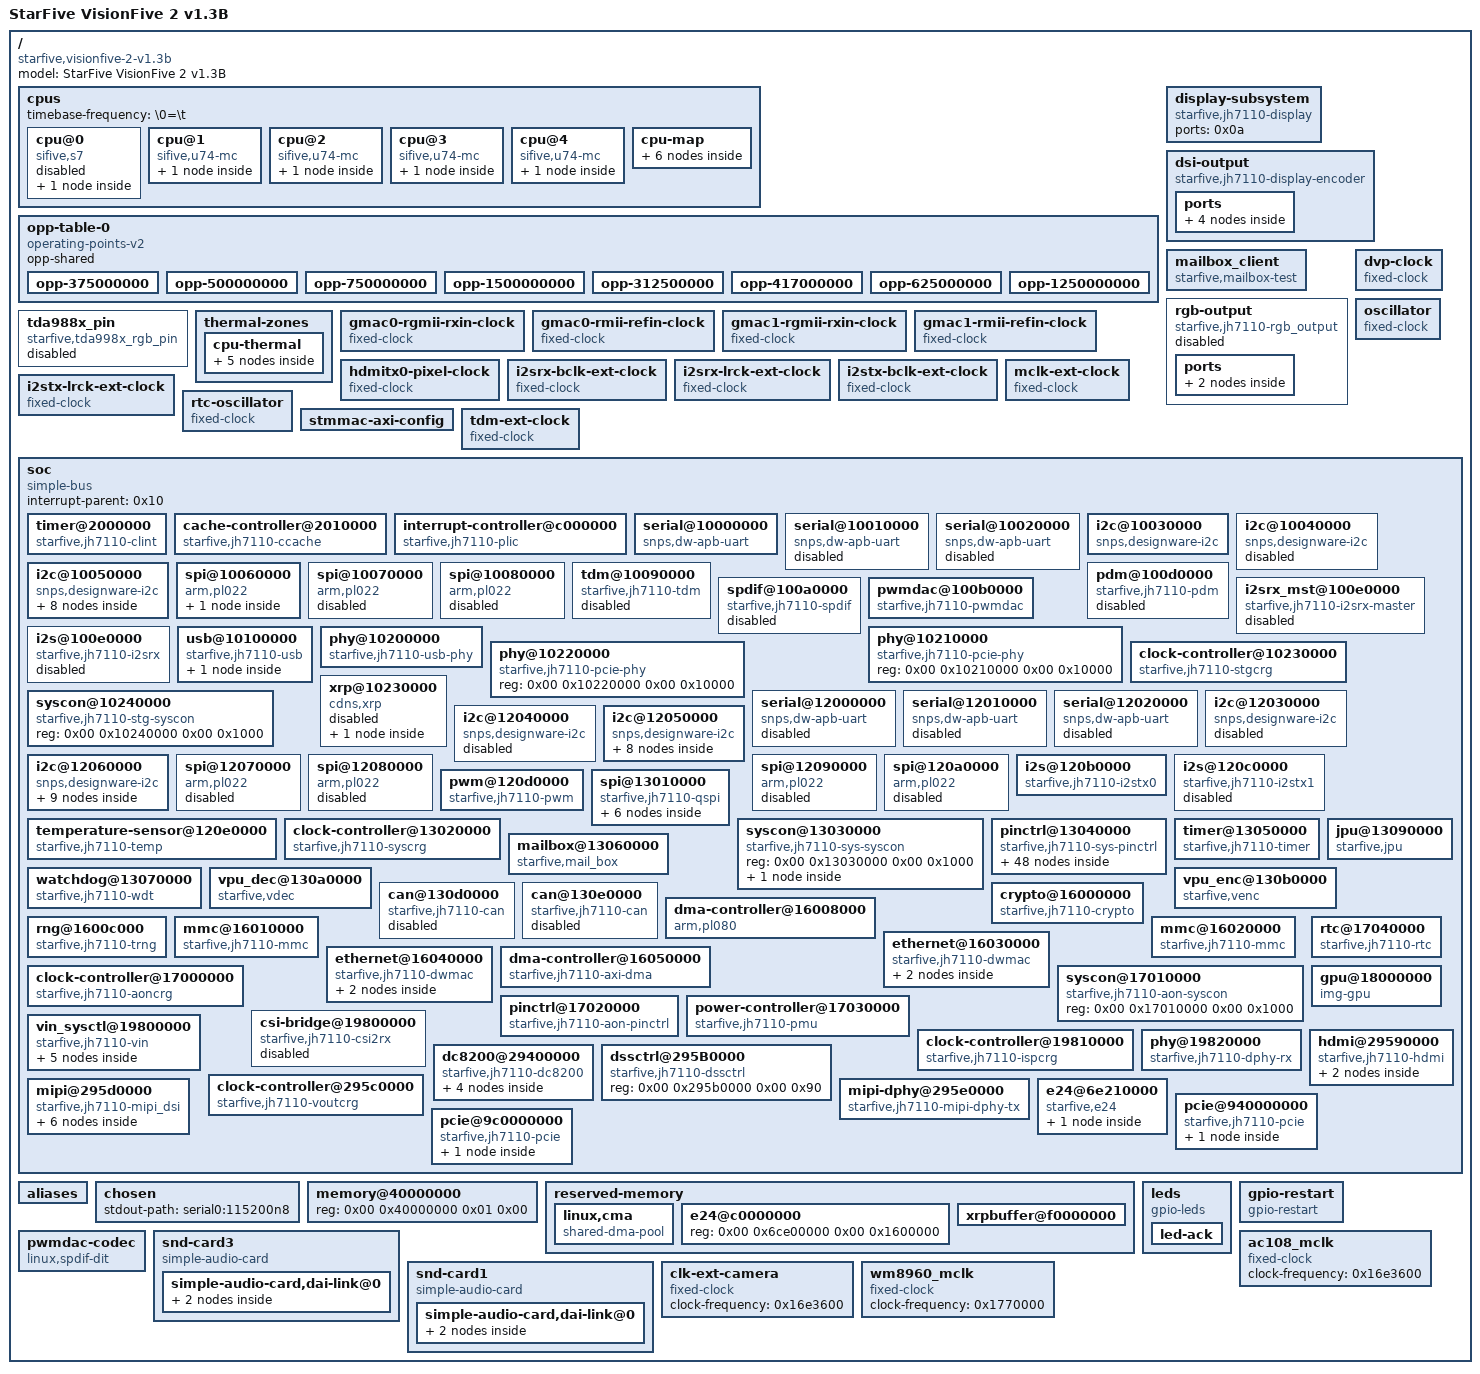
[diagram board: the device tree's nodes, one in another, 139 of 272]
/dts-v1/;

/ {
	compatible = "starfive,visionfive-2-v1.3b\0starfive,jh7110";
	#address-cells = <0x02>;
	#size-cells = <0x02>;
	model = "StarFive VisionFive 2 v1.3B";

	cpus {
		#address-cells = <0x01>;
		#size-cells = <0x00>;
		timebase-frequency = "\0=\t";

		cpu@0 {
			compatible = "sifive,s7\0riscv";
			reg = <0x00>;
			device_type = "cpu";
			i-cache-block-size = <0x40>;
			i-cache-sets = <0x40>;
			i-cache-size = <0x4000>;
			next-level-cache = <0x01>;
			riscv,isa = "rv64imac_zba_zbb";
			status = "disabled";
			phandle = <0x05>;

			interrupt-controller {
				compatible = "riscv,cpu-intc";
				interrupt-controller;
				#interrupt-cells = <0x01>;
				phandle = <0x11>;
			};
		};

		cpu@1 {
			compatible = "sifive,u74-mc\0riscv";
			reg = <0x01>;
			d-cache-block-size = <0x40>;
			d-cache-sets = <0x40>;
			d-cache-size = <0x8000>;
			d-tlb-sets = <0x01>;
			d-tlb-size = <0x28>;
			device_type = "cpu";
			i-cache-block-size = <0x40>;
			i-cache-sets = <0x40>;
			i-cache-size = <0x8000>;
			i-tlb-sets = <0x01>;
			i-tlb-size = <0x28>;
			mmu-type = "riscv,sv39";
			next-level-cache = <0x01>;
			riscv,isa = "rv64imafdc_zba_zbb";
			tlb-split;
			operating-points-v2 = <0x02>;
			clocks = <0x03 0x01>;
			clock-names = "cpu";
			#cooling-cells = <0x02>;
			cpu-supply = <0x04>;
			phandle = <0x06>;

			interrupt-controller {
				compatible = "riscv,cpu-intc";
				interrupt-controller;
				#interrupt-cells = <0x01>;
				phandle = <0x12>;
			};
		};

		cpu@2 {
			compatible = "sifive,u74-mc\0riscv";
			reg = <0x02>;
			d-cache-block-size = <0x40>;
			d-cache-sets = <0x40>;
			d-cache-size = <0x8000>;
			d-tlb-sets = <0x01>;
			d-tlb-size = <0x28>;
			device_type = "cpu";
			i-cache-block-size = <0x40>;
			i-cache-sets = <0x40>;
			i-cache-size = <0x8000>;
			i-tlb-sets = <0x01>;
			i-tlb-size = <0x28>;
			mmu-type = "riscv,sv39";
			next-level-cache = <0x01>;
			riscv,isa = "rv64imafdc_zba_zbb";
			tlb-split;
			operating-points-v2 = <0x02>;
			clocks = <0x03 0x01>;
			clock-names = "cpu";
			#cooling-cells = <0x02>;
			cpu-supply = <0x04>;
			phandle = <0x07>;

			interrupt-controller {
				compatible = "riscv,cpu-intc";
				interrupt-controller;
				#interrupt-cells = <0x01>;
				phandle = <0x13>;
			};
		};

		cpu@3 {
			compatible = "sifive,u74-mc\0riscv";
			reg = <0x03>;
			d-cache-block-size = <0x40>;
			d-cache-sets = <0x40>;
			d-cache-size = <0x8000>;
			d-tlb-sets = <0x01>;
			d-tlb-size = <0x28>;
			device_type = "cpu";
			i-cache-block-size = <0x40>;
			i-cache-sets = <0x40>;
			i-cache-size = <0x8000>;
			i-tlb-sets = <0x01>;
			i-tlb-size = <0x28>;
			mmu-type = "riscv,sv39";
			next-level-cache = <0x01>;
			riscv,isa = "rv64imafdc_zba_zbb";
			tlb-split;
			operating-points-v2 = <0x02>;
			clocks = <0x03 0x01>;
			clock-names = "cpu";
			#cooling-cells = <0x02>;
			cpu-supply = <0x04>;
			phandle = <0x08>;

			interrupt-controller {
				compatible = "riscv,cpu-intc";
				interrupt-controller;
				#interrupt-cells = <0x01>;
				phandle = <0x14>;
			};
		};

		cpu@4 {
			compatible = "sifive,u74-mc\0riscv";
			reg = <0x04>;
			d-cache-block-size = <0x40>;
			d-cache-sets = <0x40>;
			d-cache-size = <0x8000>;
			d-tlb-sets = <0x01>;
			d-tlb-size = <0x28>;
			device_type = "cpu";
			i-cache-block-size = <0x40>;
			i-cache-sets = <0x40>;
			i-cache-size = <0x8000>;
			i-tlb-sets = <0x01>;
			i-tlb-size = <0x28>;
			mmu-type = "riscv,sv39";
			next-level-cache = <0x01>;
			riscv,isa = "rv64imafdc_zba_zbb";
			tlb-split;
			operating-points-v2 = <0x02>;
			clocks = <0x03 0x01>;
			clock-names = "cpu";
			#cooling-cells = <0x02>;
			cpu-supply = <0x04>;
			phandle = <0x09>;

			interrupt-controller {
				compatible = "riscv,cpu-intc";
				interrupt-controller;
				#interrupt-cells = <0x01>;
				phandle = <0x15>;
			};
		};

		cpu-map {

			cluster0 {

				core0 {
					cpu = <0x05>;
				};

				core1 {
					cpu = <0x06>;
				};

				core2 {
					cpu = <0x07>;
				};

				core3 {
					cpu = <0x08>;
				};

				core4 {
					cpu = <0x09>;
				};
			};
		};
	};

	opp-table-0 {
		compatible = "operating-points-v2";
		opp-shared;
		phandle = <0x02>;

		opp-375000000 {
			opp-hz = <0x00 0x165a0bc0>;
			opp-microvolt = <0xdbba0>;
		};

		opp-500000000 {
			opp-hz = <0x00 0x1dcd6500>;
			opp-microvolt = <0xdbba0>;
		};

		opp-750000000 {
			opp-hz = <0x00 0x2cb41780>;
			opp-microvolt = <0xdbba0>;
			opp-suspend;
		};

		opp-1500000000 {
			opp-hz = <0x00 0x59682f00>;
			opp-microvolt = <0xfde80>;
		};

		opp-312500000 {
			opp-hz = <0x00 0x12a05f20>;
			opp-microvolt = <0xdbba0>;
		};

		opp-417000000 {
			opp-hz = <0x00 0x18daea40>;
			opp-microvolt = <0xdbba0>;
		};

		opp-625000000 {
			opp-hz = <0x00 0x2540be40>;
			opp-microvolt = <0xdbba0>;
			opp-suspend;
		};

		opp-1250000000 {
			opp-hz = <0x00 0x4a817c80>;
			opp-microvolt = <0xf4240>;
		};
	};

	display-subsystem {
		compatible = "starfive,jh7110-display\0verisilicon,display-subsystem";
		status = "okay";
		ports = <0x0a>;
		phandle = <0x69>;
	};

	dsi-output {
		compatible = "starfive,jh7110-display-encoder\0verisilicon,dsi-encoder";
		status = "okay";
		phandle = <0x6a>;

		ports {
			#address-cells = <0x01>;
			#size-cells = <0x00>;

			port@0 {
				reg = <0x00>;

				endpoint {
					remote-endpoint = <0x0b>;
					phandle = <0x52>;
				};
			};

			port@1 {
				reg = <0x01>;

				endpoint {
					remote-endpoint = <0x0c>;
					phandle = <0x5a>;
				};
			};
		};
	};

	mailbox_client {
		compatible = "starfive,mailbox-test";
		mbox-names = "rx\0tx";
		mboxes = <0x0d 0x00 0x01 0x0d 0x01 0x00>;
		status = "okay";
		phandle = <0x6b>;
	};

	rgb-output {
		compatible = "starfive,jh7110-rgb_output\0verisilicon,rgb-encoder";
		status = "disabled";
		phandle = <0x6c>;

		ports {
			#address-cells = <0x01>;
			#size-cells = <0x00>;

			port@0 {
				#address-cells = <0x01>;
				#size-cells = <0x00>;
				reg = <0x00>;

				endpoint@0 {
					reg = <0x00>;
					remote-endpoint = <0x0a>;
					phandle = <0x50>;
				};
			};
		};
	};

	tda988x_pin {
		compatible = "starfive,tda998x_rgb_pin";
		status = "disabled";
		phandle = <0x6d>;
	};

	thermal-zones {

		cpu-thermal {
			polling-delay-passive = <0xfa>;
			polling-delay = <0x3a98>;
			thermal-sensors = <0x0e>;

			cooling-maps {

				map0 {
					trip = <0x0f>;
					cooling-device = <0x06 0xffffffff 0xffffffff 0x07 0xffffffff 0xffffffff 0x08 0xffffffff 0xffffffff 0x09 0xffffffff 0xffffffff>;
				};
			};

			trips {

				cpu_alert0 {
					temperature = <0x14c08>;
					hysteresis = <0x7d0>;
					type = "passive";
					phandle = <0x0f>;
				};

				cpu_crit {
					temperature = <0x186a0>;
					hysteresis = <0x7d0>;
					type = "critical";
				};
			};
		};
	};

	dvp-clock {
		compatible = "fixed-clock";
		clock-output-names = "dvp_clk";
		#clock-cells = <0x00>;
		clock-frequency = <0x46cf710>;
		phandle = <0x4c>;
	};

	gmac0-rgmii-rxin-clock {
		compatible = "fixed-clock";
		clock-output-names = "gmac0_rgmii_rxin";
		#clock-cells = <0x00>;
		clock-frequency = <0x7735940>;
		phandle = <0x44>;
	};

	gmac0-rmii-refin-clock {
		compatible = "fixed-clock";
		clock-output-names = "gmac0_rmii_refin";
		#clock-cells = <0x00>;
		clock-frequency = <0x2faf080>;
		phandle = <0x43>;
	};

	gmac1-rgmii-rxin-clock {
		compatible = "fixed-clock";
		clock-output-names = "gmac1_rgmii_rxin";
		#clock-cells = <0x00>;
		clock-frequency = <0x7735940>;
		phandle = <0x36>;
	};

	gmac1-rmii-refin-clock {
		compatible = "fixed-clock";
		clock-output-names = "gmac1_rmii_refin";
		#clock-cells = <0x00>;
		clock-frequency = <0x2faf080>;
		phandle = <0x35>;
	};

	hdmitx0-pixel-clock {
		compatible = "fixed-clock";
		clock-output-names = "hdmitx0_pixelclk";
		#clock-cells = <0x00>;
		clock-frequency = <0x11b3dc40>;
		phandle = <0x4f>;
	};

	i2srx-bclk-ext-clock {
		compatible = "fixed-clock";
		clock-output-names = "i2srx_bclk_ext";
		#clock-cells = <0x00>;
		clock-frequency = <0xbb8000>;
		phandle = <0x23>;
	};

	i2srx-lrck-ext-clock {
		compatible = "fixed-clock";
		clock-output-names = "i2srx_lrck_ext";
		#clock-cells = <0x00>;
		clock-frequency = <0x2ee00>;
		phandle = <0x24>;
	};

	i2stx-bclk-ext-clock {
		compatible = "fixed-clock";
		clock-output-names = "i2stx_bclk_ext";
		#clock-cells = <0x00>;
		clock-frequency = <0xbb8000>;
		phandle = <0x31>;
	};

	i2stx-lrck-ext-clock {
		compatible = "fixed-clock";
		clock-output-names = "i2stx_lrck_ext";
		#clock-cells = <0x00>;
		clock-frequency = <0x2ee00>;
		phandle = <0x32>;
	};

	mclk-ext-clock {
		compatible = "fixed-clock";
		clock-output-names = "mclk_ext";
		#clock-cells = <0x00>;
		clock-frequency = <0xbb8000>;
		phandle = <0x20>;
	};

	oscillator {
		compatible = "fixed-clock";
		clock-output-names = "osc";
		#clock-cells = <0x00>;
		clock-frequency = <0x16e3600>;
		phandle = <0x29>;
	};

	rtc-oscillator {
		compatible = "fixed-clock";
		clock-output-names = "rtc_osc";
		#clock-cells = <0x00>;
		clock-frequency = <0x8000>;
		phandle = <0x45>;
	};

	stmmac-axi-config {
		snps,lpi_en;
		snps,wr_osr_lmt = <0x0f>;
		snps,rd_osr_lmt = <0x0f>;
		snps,blen = <0x100 0x80 0x40 0x20 0x00 0x00 0x00>;
		phandle = <0x3f>;
	};

	tdm-ext-clock {
		compatible = "fixed-clock";
		clock-output-names = "tdm_ext";
		#clock-cells = <0x00>;
		clock-frequency = <0x2ee0000>;
		phandle = <0x1d>;
	};

	soc {
		compatible = "simple-bus";
		interrupt-parent = <0x10>;
		#address-cells = <0x02>;
		#size-cells = <0x02>;
		ranges;

		timer@2000000 {
			compatible = "starfive,jh7110-clint\0sifive,clint0";
			reg = <0x00 0x2000000 0x00 0x10000>;
			interrupts-extended = <0x11 0x03 0x11 0x07 0x12 0x03 0x12 0x07 0x13 0x03 0x13 0x07 0x14 0x03 0x14 0x07 0x15 0x03 0x15 0x07>;
			phandle = <0x6e>;
		};

		cache-controller@2010000 {
			compatible = "starfive,jh7110-ccache\0sifive,ccache0\0cache";
			reg = <0x00 0x2010000 0x00 0x4000 0x00 0x8000000 0x00 0x2000000 0x00 0xa000000 0x00 0x2000000>;
			interrupts = <0x01 0x03 0x04 0x02>;
			cache-block-size = <0x40>;
			cache-level = <0x02>;
			cache-sets = <0x800>;
			cache-size = <0x200000>;
			cache-unified;
			phandle = <0x01>;
		};

		interrupt-controller@c000000 {
			compatible = "starfive,jh7110-plic\0sifive,plic-1.0.0";
			reg = <0x00 0xc000000 0x00 0x4000000>;
			interrupts-extended = <0x11 0x0b 0x12 0x0b 0x12 0x09 0x13 0x0b 0x13 0x09 0x14 0x0b 0x14 0x09 0x15 0x0b 0x15 0x09>;
			interrupt-controller;
			#interrupt-cells = <0x01>;
			#address-cells = <0x00>;
			riscv,ndev = <0x88>;
			phandle = <0x10>;
		};

		serial@10000000 {
			compatible = "snps,dw-apb-uart";
			reg = <0x00 0x10000000 0x00 0x10000>;
			clocks = <0x03 0x92 0x03 0x91>;
			clock-names = "baudclk\0apb_pclk";
			resets = <0x03 0x53 0x03 0x54>;
			interrupts = <0x20>;
			reg-io-width = <0x04>;
			reg-shift = <0x02>;
			status = "okay";
			pinctrl-names = "default";
			pinctrl-0 = <0x16>;
			phandle = <0x6f>;
		};

		serial@10010000 {
			compatible = "snps,dw-apb-uart";
			reg = <0x00 0x10010000 0x00 0x10000>;
			clocks = <0x03 0x94 0x03 0x93>;
			clock-names = "baudclk\0apb_pclk";
			resets = <0x03 0x55 0x03 0x56>;
			interrupts = <0x21>;
			reg-io-width = <0x04>;
			reg-shift = <0x02>;
			status = "disabled";
			phandle = <0x70>;
		};

		serial@10020000 {
			compatible = "snps,dw-apb-uart";
			reg = <0x00 0x10020000 0x00 0x10000>;
			clocks = <0x03 0x96 0x03 0x95>;
			clock-names = "baudclk\0apb_pclk";
			resets = <0x03 0x57 0x03 0x58>;
			interrupts = <0x22>;
			reg-io-width = <0x04>;
			reg-shift = <0x02>;
			status = "disabled";
			phandle = <0x71>;
		};

		i2c@10030000 {
			compatible = "snps,designware-i2c";
			reg = <0x00 0x10030000 0x00 0x10000>;
			clocks = <0x03 0x8a>;
			clock-names = "ref";
			resets = <0x03 0x4c>;
			interrupts = <0x23>;
			#address-cells = <0x01>;
			#size-cells = <0x00>;
			status = "okay";
			clock-frequency = <0x186a0>;
			i2c-sda-hold-time-ns = <0x12c>;
			i2c-sda-falling-time-ns = <0x1fe>;
			i2c-scl-falling-time-ns = <0x1fe>;
			pinctrl-names = "default";
			pinctrl-0 = <0x17>;
			phandle = <0x72>;
		};

		i2c@10040000 {
			compatible = "snps,designware-i2c";
			reg = <0x00 0x10040000 0x00 0x10000>;
			clocks = <0x03 0x8b>;
			clock-names = "ref";
			resets = <0x03 0x4d>;
			interrupts = <0x24>;
			#address-cells = <0x01>;
			#size-cells = <0x00>;
			status = "disabled";
			phandle = <0x73>;
		};

		i2c@10050000 {
			compatible = "snps,designware-i2c";
			reg = <0x00 0x10050000 0x00 0x10000>;
			clocks = <0x03 0x8c>;
			clock-names = "ref";
			resets = <0x03 0x4e>;
			interrupts = <0x25>;
			#address-cells = <0x01>;
			#size-cells = <0x00>;
			status = "okay";
			clock-frequency = <0x186a0>;
			i2c-sda-hold-time-ns = <0x12c>;
			i2c-sda-falling-time-ns = <0x1fe>;
			i2c-scl-falling-time-ns = <0x1fe>;
			pinctrl-names = "default";
			pinctrl-0 = <0x18>;
			phandle = <0x74>;

			seeed_plane_i2c@45 {
				compatible = "seeed_panel";
				reg = <0x45>;
				clock = <0x6978>;
				hdisplay = [03 20];
				hsync_start = [03 7a];
				hsync_end = [03 7f];
				htotal = [03 84];
				vdisplay = [01 e0];
				vsync_start = [02 1c];
				vsync_end = [02 21];
				vtotal = [02 26];
				dsi_dlanes = [00 01];
				dsi_bitrate = <0x2756cd00>;
				dsi_hsa = [00 78];
				dsi_hbp = [00 76];
				dsi_hfp = [00 70];
				dsi_hact = [09 60];

				port {

					endpoint {
						remote-endpoint = <0x19>;
						phandle = <0x58>;
					};
				};
			};

			tinker_ft5406@38 {
				compatible = "tinker_ft5406";
				reg = <0x38>;
				phandle = <0x75>;
			};

			touchscreen@14 {
				compatible = "goodix,gt911";
				reg = <0x14>;
				irq-gpios = <0x1a 0x1e 0x00>;
				reset-gpios = <0x1a 0x1f 0x00>;
			};

			panel_radxa@19 {
				compatible = "starfive_jadard";
				reg = <0x19>;
				reset-gpio = <0x1a 0x17 0x00>;
				enable-gpio = <0x1a 0x16 0x00>;
				mount-matrix = "1\00\00\00\0-1\00\00\00\0-1";

				port {

					endpoint {
						remote-endpoint = <0x1b>;
						phandle = <0x59>;
					};
				};
			};
		};

		spi@10060000 {
			compatible = "arm,pl022\0arm,primecell";
			reg = <0x00 0x10060000 0x00 0x10000>;
			clocks = <0x03 0x83 0x03 0x83>;
			clock-names = "sspclk\0apb_pclk";
			resets = <0x03 0x45>;
			interrupts = <0x26>;
			arm,primecell-periphid = <0x41022>;
			num-cs = <0x01>;
			#address-cells = <0x01>;
			#size-cells = <0x00>;
			status = "okay";
			pinctrl-names = "default";
			pinctrl-0 = <0x1c>;
			phandle = <0x76>;

			spi@0 {
				compatible = "rohm,dh2228fv";
				reg = <0x00>;
				spi-max-frequency = <0x989680>;
				phandle = <0x77>;
			};
		};

		spi@10070000 {
			compatible = "arm,pl022\0arm,primecell";
			reg = <0x00 0x10070000 0x00 0x10000>;
			clocks = <0x03 0x84 0x03 0x84>;
			clock-names = "sspclk\0apb_pclk";
			resets = <0x03 0x46>;
			interrupts = <0x27>;
			arm,primecell-periphid = <0x41022>;
			num-cs = <0x01>;
			#address-cells = <0x01>;
			#size-cells = <0x00>;
			status = "disabled";
			phandle = <0x78>;
		};

		spi@10080000 {
			compatible = "arm,pl022\0arm,primecell";
			reg = <0x00 0x10080000 0x00 0x10000>;
			clocks = <0x03 0x85 0x03 0x85>;
			clock-names = "sspclk\0apb_pclk";
			resets = <0x03 0x47>;
			interrupts = <0x28>;
			arm,primecell-periphid = <0x41022>;
			num-cs = <0x01>;
			#address-cells = <0x01>;
			#size-cells = <0x00>;
			status = "disabled";
			phandle = <0x79>;
		};

		tdm@10090000 {
			compatible = "starfive,jh7110-tdm";
			reg = <0x00 0x10090000 0x00 0x1000>;
			clocks = <0x03 0xb8 0x03 0xb9 0x03 0xba 0x03 0xbb 0x03 0x11 0x1d>;
			clock-names = "tdm_ahb\0tdm_apb\0tdm_internal\0tdm\0mclk_inner\0tdm_ext";
			resets = <0x03 0x69 0x03 0x6b 0x03 0x6a>;
			dmas = <0x1e 0x14 0x1e 0x15>;
			dma-names = "rx\0tx";
			#sound-dai-cells = <0x00>;
			status = "disabled";
			pinctrl-names = "default";
			pinctrl-0 = <0x1f>;
			phandle = <0x7a>;
		};

		spdif@100a0000 {
			compatible = "starfive,jh7110-spdif";
			reg = <0x00 0x100a0000 0x00 0x1000>;
			clocks = <0x03 0x9f 0x03 0xa0 0x03 0x10 0x03 0x11 0x20 0x03 0x12>;
			clock-names = "apb\0core\0audroot\0mclk_inner\0mclk_ext\0mclk";
			resets = <0x03 0x5f>;
			reset-names = "apb";
			interrupts = <0x54>;
			interrupt-names = "tx";
			#sound-dai-cells = <0x00>;
			status = "disabled";
			phandle = <0x7b>;
		};

		pwmdac@100b0000 {
			compatible = "starfive,jh7110-pwmdac";
			reg = <0x00 0x100b0000 0x00 0x1000>;
			clocks = <0x03 0x9d 0x03 0x9e>;
			clock-names = "apb\0core";
			resets = <0x03 0x60>;
			dmas = <0x1e 0x16>;
			dma-names = "tx";
			#sound-dai-cells = <0x00>;
			status = "okay";
			pinctrl-names = "default";
			pinctrl-0 = <0x21>;
			phandle = <0x64>;
		};

		pdm@100d0000 {
			compatible = "starfive,jh7110-pdm";
			reg = <0x00 0x100d0000 0x00 0x1000>;
			reg-names = "pdm";
			clocks = <0x03 0xb6 0x03 0xb7 0x03 0x12 0x20>;
			clock-names = "pdm_mclk\0pdm_apb\0clk_mclk\0mclk_ext";
			resets = <0x03 0x61 0x03 0x62>;
			reset-names = "pdm_dmic\0pdm_apb";
			#sound-dai-cells = <0x00>;
			status = "disabled";
			phandle = <0x7c>;
		};

		i2srx_mst@100e0000 {
			compatible = "starfive,jh7110-i2srx-master";
			reg = <0x00 0x100e0000 0x00 0x1000>;
			clocks = <0x03 0xb0 0x03 0xaf 0x03 0x12 0x03 0x11 0x20>;
			clock-names = "i2sclk\0apb\0mclk\0mclk_inner\0mclk_ext";
			resets = <0x03 0x63 0x03 0x64>;
			dmas = <0x1e 0x18>;
			dma-names = "rx";
			starfive,syscon = <0x22 0x18 0x02 0x34 0x3fc00 0x24400>;
			#sound-dai-cells = <0x00>;
			status = "disabled";
			phandle = <0x7d>;
		};

		i2s@100e0000 {
			compatible = "starfive,jh7110-i2srx";
			reg = <0x00 0x100e0000 0x00 0x1000>;
			clocks = <0x03 0xb0 0x03 0xaf 0x03 0x12 0x03 0x11 0x20 0x03 0xb3 0x03 0xb5 0x23 0x24>;
			clock-names = "i2sclk\0apb\0mclk\0mclk_inner\0mclk_ext\0bclk\0lrck\0bclk_ext\0lrck_ext";
			resets = <0x03 0x63 0x03 0x64>;
			dmas = <0x00 0x1e 0x18>;
			dma-names = "tx\0rx";
			starfive,syscon = <0x22 0x18 0x02>;
			#sound-dai-cells = <0x00>;
			status = "disabled";
			pinctrl-names = "default";
			pinctrl-0 = <0x25>;
			phandle = <0x7e>;
		};

		usb@10100000 {
			compatible = "starfive,jh7110-usb";
			ranges = <0x00 0x00 0x10100000 0x100000>;
			#address-cells = <0x01>;
			#size-cells = <0x01>;
			starfive,stg-syscon = <0x26 0x04>;
			clocks = <0x27 0x04 0x27 0x05 0x27 0x01 0x27 0x03 0x27 0x02>;
			clock-names = "lpm\0stb\0apb\0axi\0utmi_apb";
			resets = <0x27 0x0a 0x27 0x08 0x27 0x07 0x27 0x09>;
			reset-names = "pwrup\0apb\0axi\0utmi_apb";
			status = "okay";
			dr_mode = "peripheral";
			phandle = <0x7f>;

			usb@0 {
				compatible = "cdns,usb3";
				reg = <0x00 0x10000 0x10000 0x10000 0x20000 0x10000>;
				reg-names = "otg\0xhci\0dev";
				interrupts = <0x64 0x6c 0x6e>;
				interrupt-names = "host\0peripheral\0otg";
				phys = <0x28>;
				phy-names = "cdns3,usb2-phy";
				phandle = <0x80>;
			};
		};

		phy@10200000 {
			compatible = "starfive,jh7110-usb-phy";
			reg = <0x00 0x10200000 0x00 0x10000>;
			clocks = <0x03 0x5f 0x27 0x06>;
			clock-names = "125m\0app_125m";
			#phy-cells = <0x00>;
			phandle = <0x28>;
		};

		phy@10210000 {
			compatible = "starfive,jh7110-pcie-phy";
			reg = <0x00 0x10210000 0x00 0x10000>;
			#phy-cells = <0x00>;
			phandle = <0x5d>;
		};

		phy@10220000 {
			compatible = "starfive,jh7110-pcie-phy";
			reg = <0x00 0x10220000 0x00 0x10000>;
			#phy-cells = <0x00>;
			phandle = <0x60>;
		};

		clock-controller@10230000 {
			compatible = "starfive,jh7110-stgcrg";
			reg = <0x00 0x10230000 0x00 0x10000>;
			clocks = <0x29 0x03 0x36 0x03 0x08 0x03 0x5f 0x03 0x02 0x03 0x37 0x03 0x06 0x03 0x0b>;
			clock-names = "osc\0hifi4_core\0stg_axiahb\0usb_125m\0cpu_bus\0hifi4_axi\0nocstg_bus\0apb_bus";
			#clock-cells = <0x01>;
			#reset-cells = <0x01>;
			phandle = <0x27>;
		};

		xrp@10230000 {
			compatible = "cdns,xrp";
			dma-coherent;
			reg = <0x00 0x10230000 0x00 0x10000 0x00 0x10240000 0x00 0x10000>;
			clocks = <0x27 0x00>;
			clock-names = "core_clk";
			resets = <0x27 0x01 0x27 0x02>;
			reset-names = "rst_core\0rst_axi";
			starfive,stg-syscon = <0x26>;
			firmware-name = "hifi4_elf";
			#address-cells = <0x01>;
			#size-cells = <0x01>;
			ranges = <0x40000000 0x00 0x20000000 0x40000 0x69c00000 0x00 0x69c00000 0x3000000>;
			status = "disabled";
			phandle = <0x81>;

			dsp@0 {
			};
		};

		syscon@10240000 {
			compatible = "starfive,jh7110-stg-syscon\0syscon";
			reg = <0x00 0x10240000 0x00 0x1000>;
			phandle = <0x26>;
		};

		serial@12000000 {
			compatible = "snps,dw-apb-uart";
			reg = <0x00 0x12000000 0x00 0x10000>;
			clocks = <0x03 0x98 0x03 0x97>;
			clock-names = "baudclk\0apb_pclk";
			resets = <0x03 0x59 0x03 0x5a>;
			interrupts = <0x2d>;
			reg-io-width = <0x04>;
			reg-shift = <0x02>;
			status = "disabled";
			phandle = <0x82>;
		};

		serial@12010000 {
			compatible = "snps,dw-apb-uart";
			reg = <0x00 0x12010000 0x00 0x10000>;
			clocks = <0x03 0x9a 0x03 0x99>;
			clock-names = "baudclk\0apb_pclk";
			resets = <0x03 0x5b 0x03 0x5c>;
			interrupts = <0x2e>;
			reg-io-width = <0x04>;
			reg-shift = <0x02>;
			status = "disabled";
			phandle = <0x83>;
		};

		serial@12020000 {
			compatible = "snps,dw-apb-uart";
			reg = <0x00 0x12020000 0x00 0x10000>;
			clocks = <0x03 0x9c 0x03 0x9b>;
			clock-names = "baudclk\0apb_pclk";
			resets = <0x03 0x5d 0x03 0x5e>;
			interrupts = <0x2f>;
			reg-io-width = <0x04>;
			reg-shift = <0x02>;
			status = "disabled";
			phandle = <0x84>;
		};

		i2c@12030000 {
			compatible = "snps,designware-i2c";
			reg = <0x00 0x12030000 0x00 0x10000>;
			clocks = <0x03 0x8d>;
			clock-names = "ref";
			resets = <0x03 0x4f>;
			interrupts = <0x30>;
			#address-cells = <0x01>;
			#size-cells = <0x00>;
			status = "disabled";
			phandle = <0x85>;
		};

		i2c@12040000 {
			compatible = "snps,designware-i2c";
			reg = <0x00 0x12040000 0x00 0x10000>;
			clocks = <0x03 0x8e>;
			clock-names = "ref";
			resets = <0x03 0x50>;
			interrupts = <0x31>;
			#address-cells = <0x01>;
			#size-cells = <0x00>;
			status = "disabled";
			phandle = <0x86>;
		};

		i2c@12050000 {
			compatible = "snps,designware-i2c";
			reg = <0x00 0x12050000 0x00 0x10000>;
			clocks = <0x03 0x8f>;
			clock-names = "ref";
			resets = <0x03 0x51>;
			interrupts = <0x32>;
			#address-cells = <0x01>;
			#size-cells = <0x00>;
			status = "okay";
			clock-frequency = <0x186a0>;
			i2c-sda-hold-time-ns = <0x12c>;
			i2c-sda-falling-time-ns = <0x1fe>;
			i2c-scl-falling-time-ns = <0x1fe>;
			pinctrl-names = "default";
			pinctrl-0 = <0x2a>;
			phandle = <0x87>;

			pmic@36 {
				compatible = "x-powers,axp15060";
				reg = <0x36>;
				interrupts = <0x00>;
				interrupt-controller;
				#interrupt-cells = <0x01>;
				phandle = <0x88>;

				regulators {

					ALDO1 {
						regulator-boot-on;
						regulator-compatible = "aldo1";
						regulator-name = "mipi_0p9";
						regulator-min-microvolt = <0xdbba0>;
						regulator-max-microvolt = <0xdbba0>;
						phandle = <0x48>;
					};

					ALDO5 {
						regulator-boot-on;
						regulator-compatible = "aldo5";
						regulator-name = "hdmi_0p9";
						regulator-min-microvolt = <0xdbba0>;
						regulator-max-microvolt = <0xdbba0>;
						phandle = <0x54>;
					};

					ALDO3 {
						regulator-boot-on;
						regulator-compatible = "aldo3";
						regulator-name = "hdmi_1p8";
						regulator-min-microvolt = <0x1b7740>;
						regulator-max-microvolt = <0x1b7740>;
						phandle = <0x55>;
					};

					dcdc1 {
						regulator-boot-on;
						regulator-always-on;
						regulator-min-microvolt = <0x325aa0>;
						regulator-max-microvolt = <0x325aa0>;
						regulator-compatible = "dcdc1";
						regulator-name = "vcc_3v3";
						phandle = <0x3b>;
					};

					dcdc2 {
						regulator-always-on;
						regulator-min-microvolt = <0x7a120>;
						regulator-max-microvolt = <0x177fa0>;
						regulator-compatible = "dcdc2";
						regulator-name = "vdd-cpu";
						phandle = <0x04>;
					};

					aldo4 {
						regulator-boot-on;
						regulator-always-on;
						regulator-min-microvolt = <0x1b7740>;
						regulator-max-microvolt = <0x1b7740>;
						regulator-compatible = "aldo4";
						regulator-name = "emmc_vdd";
						phandle = <0x3c>;
					};
				};
			};
		};

		i2c@12060000 {
			compatible = "snps,designware-i2c";
			reg = <0x00 0x12060000 0x00 0x10000>;
			clocks = <0x03 0x90>;
			clock-names = "ref";
			resets = <0x03 0x52>;
			interrupts = <0x33>;
			#address-cells = <0x01>;
			#size-cells = <0x00>;
			status = "okay";
			clock-frequency = <0x186a0>;
			i2c-sda-hold-time-ns = <0x12c>;
			i2c-sda-falling-time-ns = <0x1fe>;
			i2c-scl-falling-time-ns = <0x1fe>;
			pinctrl-names = "default";
			pinctrl-0 = <0x2b>;
			phandle = <0x89>;

			imx219@10 {
				compatible = "sony,imx219";
				reg = <0x10>;
				clocks = <0x2c>;
				clock-names = "xclk";
				reset-gpio = <0x1a 0x12 0x00>;
				rotation = <0x00>;
				orientation = <0x01>;
				phandle = <0x8a>;

				port {

					endpoint {
						remote-endpoint = <0x2d>;
						bus-type = <0x04>;
						clock-lanes = <0x04>;
						data-lanes = <0x00 0x01>;
						lane-polarities = <0x00 0x00 0x00>;
						link-frequencies = <0x00 0x1b2e0200>;
						phandle = <0x49>;
					};
				};
			};

			imx708@1a {
				compatible = "sony,imx708";
				reg = <0x1a>;
				clocks = <0x2c>;
				reset-gpio = <0x1a 0x12 0x00>;
				phandle = <0x8b>;

				port {

					endpoint {
						remote-endpoint = <0x2e>;
						data-lanes = <0x01 0x02>;
						clock-noncontinuous;
						link-frequencies = <0x00 0x1ad27480>;
						phandle = <0x4a>;
					};
				};
			};

			ov4689@36 {
				compatible = "ovti,ov4689";
				reg = <0x36>;
				clocks = <0x2c>;
				clock-names = "xclk";
				rotation = <0xb4>;
				phandle = <0x8c>;

				port {

					endpoint {
						remote-endpoint = <0x2f>;
						bus-type = <0x04>;
						clock-lanes = <0x00>;
						data-lanes = <0x01 0x02>;
						phandle = <0x4b>;
					};
				};
			};
		};

		spi@12070000 {
			compatible = "arm,pl022\0arm,primecell";
			reg = <0x00 0x12070000 0x00 0x10000>;
			clocks = <0x03 0x86 0x03 0x86>;
			clock-names = "sspclk\0apb_pclk";
			resets = <0x03 0x48>;
			interrupts = <0x34>;
			arm,primecell-periphid = <0x41022>;
			num-cs = <0x01>;
			#address-cells = <0x01>;
			#size-cells = <0x00>;
			status = "disabled";
			phandle = <0x8d>;
		};

		spi@12080000 {
			compatible = "arm,pl022\0arm,primecell";
			reg = <0x00 0x12080000 0x00 0x10000>;
			clocks = <0x03 0x87 0x03 0x87>;
			clock-names = "sspclk\0apb_pclk";
			resets = <0x03 0x49>;
			interrupts = <0x35>;
			arm,primecell-periphid = <0x41022>;
			num-cs = <0x01>;
			#address-cells = <0x01>;
			#size-cells = <0x00>;
			status = "disabled";
			phandle = <0x8e>;
		};

		spi@12090000 {
			compatible = "arm,pl022\0arm,primecell";
			reg = <0x00 0x12090000 0x00 0x10000>;
			clocks = <0x03 0x88 0x03 0x88>;
			clock-names = "sspclk\0apb_pclk";
			resets = <0x03 0x4a>;
			interrupts = <0x36>;
			arm,primecell-periphid = <0x41022>;
			num-cs = <0x01>;
			#address-cells = <0x01>;
			#size-cells = <0x00>;
			status = "disabled";
			phandle = <0x8f>;
		};

		spi@120a0000 {
			compatible = "arm,pl022\0arm,primecell";
			reg = <0x00 0x120a0000 0x00 0x10000>;
			clocks = <0x03 0x89 0x03 0x89>;
			clock-names = "sspclk\0apb_pclk";
			resets = <0x03 0x4b>;
			interrupts = <0x37>;
			arm,primecell-periphid = <0x41022>;
			num-cs = <0x01>;
			#address-cells = <0x01>;
			#size-cells = <0x00>;
			status = "disabled";
			phandle = <0x90>;
		};

		i2s@120b0000 {
			compatible = "starfive,jh7110-i2stx0";
			reg = <0x00 0x120b0000 0x00 0x1000>;
			clocks = <0x03 0xa2 0x03 0xa1 0x03 0x12 0x03 0x11 0x20>;
			clock-names = "i2sclk\0apb\0mclk\0mclk_inner\0mclk_ext";
			resets = <0x03 0x65 0x03 0x66>;
			dmas = <0x1e 0x2f>;
			dma-names = "tx";
			#sound-dai-cells = <0x00>;
			status = "okay";
			pinctrl-names = "default";
			pinctrl-0 = <0x30>;
			phandle = <0x67>;
		};

		i2s@120c0000 {
			compatible = "starfive,jh7110-i2stx1";
			reg = <0x00 0x120c0000 0x00 0x1000>;
			clocks = <0x03 0xa9 0x03 0xa8 0x03 0x12 0x03 0x11 0x20 0x03 0xac 0x03 0xae 0x31 0x32>;
			clock-names = "i2sclk\0apb\0mclk\0mclk_inner\0mclk_ext\0bclk\0lrck\0bclk_ext\0lrck_ext";
			resets = <0x03 0x67 0x03 0x68>;
			dmas = <0x1e 0x30>;
			dma-names = "tx";
			#sound-dai-cells = <0x00>;
			status = "disabled";
			pinctrl-names = "default";
			pinctrl-0 = <0x33>;
			phandle = <0x91>;
		};

		pwm@120d0000 {
			compatible = "starfive,jh7110-pwm\0opencores,pwm-v1";
			reg = <0x00 0x120d0000 0x00 0x10000>;
			clocks = <0x03 0x79>;
			resets = <0x03 0x6c>;
			#pwm-cells = <0x03>;
			status = "okay";
			pinctrl-names = "default";
			pinctrl-0 = <0x34>;
			phandle = <0x92>;
		};

		temperature-sensor@120e0000 {
			compatible = "starfive,jh7110-temp";
			reg = <0x00 0x120e0000 0x00 0x10000>;
			clocks = <0x03 0x82 0x03 0x81>;
			clock-names = "sense\0bus";
			resets = <0x03 0x7c 0x03 0x7b>;
			reset-names = "sense\0bus";
			#thermal-sensor-cells = <0x00>;
			phandle = <0x0e>;
		};

		spi@13010000 {
			compatible = "starfive,jh7110-qspi\0cdns,qspi-nor";
			reg = <0x00 0x13010000 0x00 0x10000 0x00 0x21000000 0x00 0x400000>;
			interrupts = <0x19>;
			clocks = <0x03 0x5a 0x03 0x57 0x03 0x58>;
			clock-names = "ref\0ahb\0apb";
			resets = <0x03 0x3e 0x03 0x3d 0x03 0x3f>;
			reset-names = "qspi\0qspi-ocp\0rstc_ref";
			cdns,fifo-depth = <0x100>;
			cdns,fifo-width = <0x04>;
			cdns,trigger-address = <0x00>;
			status = "okay";
			#address-cells = <0x01>;
			#size-cells = <0x00>;
			phandle = <0x93>;

			flash@0 {
				compatible = "jedec,spi-nor";
				reg = <0x00>;
				cdns,read-delay = <0x05>;
				spi-max-frequency = <0xb71b00>;
				cdns,tshsl-ns = <0x01>;
				cdns,tsd2d-ns = <0x01>;
				cdns,tchsh-ns = <0x01>;
				cdns,tslch-ns = <0x01>;
				phandle = <0x94>;

				partitions {
					compatible = "fixed-partitions";
					#address-cells = <0x01>;
					#size-cells = <0x01>;

					spl@0 {
						reg = <0x00 0x80000>;
					};

					uboot-env@f0000 {
						reg = <0xf0000 0x10000>;
					};

					uboot@100000 {
						reg = <0x100000 0x400000>;
					};

					reserved-data@600000 {
						reg = <0x600000 0xa00000>;
					};
				};
			};
		};

		clock-controller@13020000 {
			compatible = "starfive,jh7110-syscrg";
			reg = <0x00 0x13020000 0x00 0x10000>;
			clocks = <0x29 0x35 0x36 0x31 0x32 0x23 0x24 0x1d 0x20 0x37 0x00 0x37 0x01 0x37 0x02>;
			clock-names = "osc\0gmac1_rmii_refin\0gmac1_rgmii_rxin\0i2stx_bclk_ext\0i2stx_lrck_ext\0i2srx_bclk_ext\0i2srx_lrck_ext\0tdm_ext\0mclk_ext\0pll0_out\0pll1_out\0pll2_out";
			#clock-cells = <0x01>;
			#reset-cells = <0x01>;
			phandle = <0x03>;
		};

		syscon@13030000 {
			compatible = "starfive,jh7110-sys-syscon\0syscon\0simple-mfd";
			reg = <0x00 0x13030000 0x00 0x1000>;
			phandle = <0x22>;

			clock-controller {
				compatible = "starfive,jh7110-pll";
				clocks = <0x29>;
				#clock-cells = <0x01>;
				phandle = <0x37>;
			};
		};

		pinctrl@13040000 {
			compatible = "starfive,jh7110-sys-pinctrl";
			reg = <0x00 0x13040000 0x00 0x10000>;
			clocks = <0x03 0x70>;
			resets = <0x03 0x02>;
			interrupts = <0x56>;
			interrupt-controller;
			#interrupt-cells = <0x02>;
			gpio-controller;
			#gpio-cells = <0x02>;
			phandle = <0x1a>;

			i2c0-0 {
				phandle = <0x17>;

				i2c-pins {
					pinmux = <0x9001439 0xa00183a>;
					bias-disable;
					input-enable;
					input-schmitt-enable;
				};
			};

			i2c2-0 {
				phandle = <0x18>;

				i2c-pins {
					pinmux = <0x3b007803 0x3c007c02>;
					bias-disable;
					input-enable;
					input-schmitt-enable;
				};
			};

			i2c5-0 {
				phandle = <0x2a>;

				i2c-pins {
					pinmux = <0x4f00a813 0x5000ac14>;
					bias-disable;
					input-enable;
					input-schmitt-enable;
				};
			};

			i2c6-0 {
				phandle = <0x2b>;

				i2c-pins {
					pinmux = <0x5600b810 0x5700bc11>;
					bias-disable;
					input-enable;
					input-schmitt-enable;
				};
			};

			i2srx-0 {
				phandle = <0x25>;

				clk-sd-pins {
					pinmux = <0x1f000426 0x2000043f 0x21000426 0x2200043f 0x1700043d>;
					input-enable;
				};
			};

			i2stx1-0 {
				phandle = <0x33>;

				sd-pins {
					pinmux = <0xff45002c>;
					bias-disable;
					input-disable;
				};
			};

			mclk-ext-0 {
				phandle = <0x30>;

				mclk-ext-pins {
					pinmux = <0x1e000404>;
					input-enable;
				};
			};

			mmc0-0 {
				phandle = <0x3a>;

				rst-pins {
					pinmux = <0xff13003e>;
					bias-pull-up;
					drive-strength = <0x0c>;
					input-disable;
					input-schmitt-disable;
					slew-rate = <0x00>;
				};

				mmc-pins {
					pinmux = <0x440 0x441 0x442 0x443 0x444 0x445 0x446 0x447 0x448 0x449>;
					bias-pull-up;
					drive-strength = <0x0c>;
					input-enable;
				};
			};

			mmc1-0 {
				phandle = <0x3d>;

				clk-pins {
					pinmux = <0xff37000a>;
					bias-pull-up;
					drive-strength = <0x0c>;
					input-disable;
					input-schmitt-disable;
					slew-rate = <0x00>;
				};

				mmc-pins {
					pinmux = <0x2c394c09 0x2d3a500b 0x2e3b540c 0x2f3c5807 0x303d5c08>;
					bias-pull-up;
					drive-strength = <0x0c>;
					input-enable;
					input-schmitt-enable;
					slew-rate = <0x00>;
				};
			};

			pcie0-0 {
				phandle = <0x5e>;

				clkreq-pins {
					pinmux = <0xff00041b>;
					bias-pull-down;
					drive-strength = <0x02>;
					input-enable;
					input-schmitt-disable;
					slew-rate = <0x00>;
				};

				wake-pins {
					pinmux = <0xff000420>;
					bias-pull-up;
					drive-strength = <0x02>;
					input-enable;
					input-schmitt-disable;
					slew-rate = <0x00>;
				};
			};

			pcie1-0 {
				phandle = <0x61>;

				clkreq-pins {
					pinmux = <0xff00041d>;
					bias-pull-down;
					drive-strength = <0x02>;
					input-enable;
					input-schmitt-disable;
					slew-rate = <0x00>;
				};

				wake-pins {
					pinmux = <0xff000415>;
					bias-pull-up;
					drive-strength = <0x02>;
					input-enable;
					input-schmitt-disable;
					slew-rate = <0x00>;
				};
			};

			pwm-0 {
				phandle = <0x34>;

				pwm-pins {
					pinmux = <0xff18242e 0xff19283b>;
					bias-disable;
					drive-strength = <0x0c>;
					input-disable;
					input-schmitt-disable;
					slew-rate = <0x00>;
				};
			};

			pwmdac-0 {
				phandle = <0x21>;

				pwmdac-pins {
					pinmux = <0xff1c0021 0xff1d0022>;
					bias-disable;
					drive-strength = <0x02>;
					input-disable;
					input-schmitt-disable;
					slew-rate = <0x00>;
				};
			};

			spi0-0 {
				phandle = <0x1c>;

				mosi-pins {
					pinmux = <0xff200034>;
					bias-disable;
					input-disable;
					input-schmitt-disable;
				};

				miso-pins {
					pinmux = <0x1c000435>;
					bias-pull-up;
					input-enable;
					input-schmitt-enable;
				};

				sck-pins {
					pinmux = <0x1a1e0030>;
					bias-disable;
					input-disable;
					input-schmitt-disable;
				};

				ss-pins {
					pinmux = <0x1b1f0031>;
					bias-disable;
					input-disable;
					input-schmitt-disable;
				};
			};

			tdm-0 {
				phandle = <0x1f>;

				tx-pins {
					pinmux = <0xff29002c>;
					bias-pull-up;
					drive-strength = <0x02>;
					input-disable;
					input-schmitt-disable;
					slew-rate = <0x00>;
				};

				rx-pins {
					pinmux = <0x2401043d>;
					input-enable;
				};

				sync-pins {
					pinmux = <0x2501043f>;
					input-enable;
				};

				pcmclk-pins {
					pinmux = <0x23010426>;
					input-enable;
				};
			};

			uart0-0 {
				phandle = <0x16>;

				tx-pins {
					pinmux = <0xff140005>;
					bias-disable;
					drive-strength = <0x0c>;
					input-disable;
					input-schmitt-disable;
					slew-rate = <0x00>;
				};

				rx-pins {
					pinmux = <0xe000406>;
					bias-disable;
					drive-strength = <0x02>;
					input-enable;
					input-schmitt-enable;
					slew-rate = <0x00>;
				};
			};

			hdmi-0 {
				phandle = <0x53>;

				scl-pins {
					pinmux = <0x60b0c00>;
					bias-pull-up;
					input-enable;
				};

				sda-pins {
					pinmux = <0x70c1001>;
					bias-pull-up;
					input-enable;
				};

				cec-pins {
					pinmux = <0x50a080e>;
					bias-pull-up;
					input-enable;
				};

				hpd-pins {
					pinmux = <0x800040f>;
					bias-disable;
					input-enable;
				};
			};
		};

		timer@13050000 {
			compatible = "starfive,jh7110-timer";
			reg = <0x00 0x13050000 0x00 0x10000>;
			interrupts = <0x45 0x46 0x47 0x48>;
			clocks = <0x03 0x7c 0x03 0x7d 0x03 0x7e 0x03 0x7f 0x03 0x80>;
			clock-names = "apb\0ch0\0ch1\0ch2\0ch3";
			resets = <0x03 0x75 0x03 0x76 0x03 0x77 0x03 0x78 0x03 0x79>;
			reset-names = "apb\0ch0\0ch1\0ch2\0ch3";
		};

		mailbox@13060000 {
			compatible = "starfive,mail_box";
			reg = <0x00 0x13060000 0x00 0x1000>;
			clocks = <0x03 0x71>;
			clock-names = "clk_apb";
			resets = <0x03 0x44>;
			reset-names = "mbx_rre";
			interrupts = <0x1a 0x1b>;
			#mbox-cells = <0x02>;
			status = "okay";
			phandle = <0x0d>;
		};

		watchdog@13070000 {
			compatible = "starfive,jh7110-wdt";
			reg = <0x00 0x13070000 0x00 0x10000>;
			clocks = <0x03 0x7a 0x03 0x7b>;
			clock-names = "apb\0core";
			resets = <0x03 0x6d 0x03 0x6e>;
		};

		jpu@13090000 {
			compatible = "starfive,jpu";
			dma-coherent;
			reg = <0x00 0x13090000 0x00 0x300>;
			interrupts = <0x0e>;
			clocks = <0x03 0x42 0x03 0x43 0x03 0x44 0x03 0x4c 0x03 0x4b 0x03 0x4a>;
			clock-names = "axi_clk\0core_clk\0apb_clk\0noc_bus\0main_clk\0dec_clk";
			resets = <0x03 0x2c 0x03 0x2d 0x03 0x2e>;
			reset-names = "rst_axi\0rst_core\0rst_apb";
			power-domains = <0x38 0x03>;
			status = "okay";
			phandle = <0x95>;
		};

		vpu_dec@130a0000 {
			compatible = "starfive,vdec";
			dma-coherent;
			reg = <0x00 0x130a0000 0x00 0x10000>;
			interrupts = <0x0d>;
			clocks = <0x03 0x46 0x03 0x47 0x03 0x48 0x03 0x49 0x03 0x4c 0x03 0x4b>;
			clock-names = "axi_clk\0bpu_clk\0vce_clk\0apb_clk\0noc_bus\0main_clk";
			resets = <0x03 0x2f 0x03 0x30 0x03 0x31 0x03 0x32 0x03 0x35>;
			reset-names = "rst_axi\0rst_bpu\0rst_vce\0rst_apb\0rst_sram";
			starfive,vdec_noc_ctrl;
			power-domains = <0x38 0x03>;
			status = "okay";
			phandle = <0x96>;
		};

		vpu_enc@130b0000 {
			compatible = "starfive,venc";
			dma-coherent;
			reg = <0x00 0x130b0000 0x00 0x10000>;
			interrupts = <0x0f>;
			clocks = <0x03 0x4e 0x03 0x4f 0x03 0x50 0x03 0x51 0x03 0x52>;
			clock-names = "axi_clk\0bpu_clk\0vce_clk\0apb_clk\0noc_bus";
			resets = <0x03 0x36 0x03 0x37 0x03 0x38 0x03 0x39 0x03 0x3a>;
			reset-names = "rst_axi\0rst_bpu\0rst_vce\0rst_apb\0rst_sram";
			starfive,venc_noc_ctrl;
			power-domains = <0x38 0x06>;
			status = "okay";
			phandle = <0x97>;
		};

		can@130d0000 {
			compatible = "starfive,jh7110-can\0ipms,can";
			reg = <0x00 0x130d0000 0x00 0x1000>;
			interrupts = <0x70>;
			clocks = <0x03 0x73 0x03 0x75 0x03 0x74>;
			clock-names = "apb_clk\0core_clk\0timer_clk";
			resets = <0x03 0x6f 0x03 0x70 0x03 0x71>;
			reset-names = "rst_apb\0rst_core\0rst_timer";
			frequency = <0x2625a00>;
			starfive,sys-syscon = <0x22 0x10 0x03 0x08>;
			syscon,can_or_canfd = <0x00>;
			status = "disabled";
			phandle = <0x98>;
		};

		can@130e0000 {
			compatible = "starfive,jh7110-can\0ipms,can";
			reg = <0x00 0x130e0000 0x00 0x1000>;
			interrupts = <0x71>;
			clocks = <0x03 0x76 0x03 0x78 0x03 0x77>;
			clock-names = "apb_clk\0core_clk\0timer_clk";
			resets = <0x03 0x72 0x03 0x73 0x03 0x74>;
			reset-names = "rst_apb\0rst_core\0rst_timer";
			frequency = <0x2625a00>;
			starfive,sys-syscon = <0x22 0x88 0x12 0x40000>;
			syscon,can_or_canfd = <0x00>;
			status = "disabled";
			phandle = <0x99>;
		};

		crypto@16000000 {
			compatible = "starfive,jh7110-crypto";
			reg = <0x00 0x16000000 0x00 0x4000>;
			clocks = <0x27 0x0f 0x27 0x10>;
			clock-names = "hclk\0ahb";
			interrupts = <0x1c>;
			resets = <0x27 0x03>;
			dmas = <0x39 0x01 0x02 0x39 0x00 0x02>;
			dma-names = "tx\0rx";
			phandle = <0x9a>;
		};

		dma-controller@16008000 {
			compatible = "arm,pl080\0arm,primecell";
			arm,primecell-periphid = <0x41080>;
			reg = <0x00 0x16008000 0x00 0x4000>;
			interrupts = <0x1d>;
			clocks = <0x27 0x0f>;
			clock-names = "apb_pclk";
			resets = <0x27 0x03>;
			lli-bus-interface-ahb1;
			mem-bus-interface-ahb1;
			memcpy-burst-size = <0x100>;
			memcpy-bus-width = <0x20>;
			#dma-cells = <0x02>;
			phandle = <0x39>;
		};

		rng@1600c000 {
			compatible = "starfive,jh7110-trng";
			reg = <0x00 0x1600c000 0x00 0x4000>;
			clocks = <0x27 0x0f 0x27 0x10>;
			clock-names = "hclk\0ahb";
			resets = <0x27 0x03>;
			interrupts = <0x1e>;
			phandle = <0x9b>;
		};

		mmc@16010000 {
			compatible = "starfive,jh7110-mmc";
			reg = <0x00 0x16010000 0x00 0x10000>;
			clocks = <0x03 0x5b 0x03 0x5d>;
			clock-names = "biu\0ciu";
			resets = <0x03 0x40>;
			reset-names = "reset";
			interrupts = <0x4a>;
			fifo-depth = <0x20>;
			fifo-watermark-aligned;
			data-addr = <0x00>;
			starfive,sysreg = <0x22 0x14 0x1a 0x7c000000>;
			status = "okay";
			max-frequency = <0x5f5e100>;
			assigned-clocks = <0x03 0x5d>;
			assigned-clock-rates = <0x2faf080>;
			bus-width = <0x08>;
			cap-mmc-highspeed;
			mmc-ddr-1_8v;
			mmc-hs200-1_8v;
			non-removable;
			cap-mmc-hw-reset;
			post-power-on-delay-ms = <0xc8>;
			pinctrl-names = "default";
			pinctrl-0 = <0x3a>;
			vmmc-supply = <0x3b>;
			vqmmc-supply = <0x3c>;
			phandle = <0x9c>;
		};

		mmc@16020000 {
			compatible = "starfive,jh7110-mmc";
			reg = <0x00 0x16020000 0x00 0x10000>;
			clocks = <0x03 0x5c 0x03 0x5e>;
			clock-names = "biu\0ciu";
			resets = <0x03 0x41>;
			reset-names = "reset";
			interrupts = <0x4b>;
			fifo-depth = <0x20>;
			fifo-watermark-aligned;
			data-addr = <0x00>;
			starfive,sysreg = <0x22 0x9c 0x01 0x3e>;
			status = "okay";
			max-frequency = <0x5f5e100>;
			assigned-clocks = <0x03 0x5e>;
			assigned-clock-rates = <0x2faf080>;
			bus-width = <0x04>;
			no-sdio;
			no-mmc;
			broken-cd;
			cap-sd-highspeed;
			post-power-on-delay-ms = <0xc8>;
			pinctrl-names = "default";
			pinctrl-0 = <0x3d>;
			phandle = <0x9d>;
		};

		ethernet@16030000 {
			compatible = "starfive,jh7110-dwmac\0snps,dwmac-5.20";
			reg = <0x00 0x16030000 0x00 0x10000>;
			clocks = <0x3e 0x03 0x3e 0x02 0x03 0x6d 0x3e 0x06 0x03 0x6f>;
			clock-names = "stmmaceth\0pclk\0ptp_ref\0tx\0gtx";
			resets = <0x3e 0x00 0x3e 0x01>;
			reset-names = "stmmaceth\0ahb";
			interrupts = <0x07 0x06 0x05>;
			interrupt-names = "macirq\0eth_wake_irq\0eth_lpi";
			rx-fifo-depth = <0x800>;
			tx-fifo-depth = <0x800>;
			snps,multicast-filter-bins = <0x40>;
			snps,perfect-filter-entries = <0x100>;
			snps,fixed-burst;
			snps,no-pbl-x8;
			snps,force_thresh_dma_mode;
			snps,axi-config = <0x3f>;
			snps,tso;
			snps,en-tx-lpi-clockgating;
			snps,txpbl = <0x10>;
			snps,rxpbl = <0x10>;
			starfive,syscon = <0x40 0x0c 0x12>;
			status = "okay";
			phy-handle = <0x41>;
			phy-mode = "rgmii-id";
			starfive,tx-use-rgmii-clk;
			assigned-clocks = <0x3e 0x05>;
			assigned-clock-parents = <0x3e 0x04>;
			phandle = <0x9e>;

			mdio {
				#address-cells = <0x01>;
				#size-cells = <0x00>;
				compatible = "snps,dwmac-mdio";

				ethernet-phy@0 {
					reg = <0x00>;
					motorcomm,tx-clk-adj-enabled;
					motorcomm,tx-clk-100-inverted;
					motorcomm,tx-clk-1000-inverted;
					motorcomm,rx-clk-drv-microamp = <0xf82>;
					motorcomm,rx-data-drv-microamp = <0xb5e>;
					rx-internal-delay-ps = <0x5dc>;
					tx-internal-delay-ps = <0x5dc>;
					phandle = <0x41>;
				};
			};
		};

		ethernet@16040000 {
			compatible = "starfive,jh7110-dwmac\0snps,dwmac-5.20";
			reg = <0x00 0x16040000 0x00 0x10000>;
			clocks = <0x03 0x62 0x03 0x61 0x03 0x66 0x03 0x6a 0x03 0x6b>;
			clock-names = "stmmaceth\0pclk\0ptp_ref\0tx\0gtx";
			resets = <0x03 0x42 0x03 0x43>;
			reset-names = "stmmaceth\0ahb";
			interrupts = <0x4e 0x4d 0x4c>;
			interrupt-names = "macirq\0eth_wake_irq\0eth_lpi";
			rx-fifo-depth = <0x800>;
			tx-fifo-depth = <0x800>;
			snps,multicast-filter-bins = <0x40>;
			snps,perfect-filter-entries = <0x100>;
			snps,fixed-burst;
			snps,no-pbl-x8;
			snps,force_thresh_dma_mode;
			snps,axi-config = <0x3f>;
			snps,tso;
			snps,en-tx-lpi-clockgating;
			snps,txpbl = <0x10>;
			snps,rxpbl = <0x10>;
			starfive,syscon = <0x22 0x90 0x02>;
			status = "okay";
			phy-handle = <0x42>;
			phy-mode = "rgmii-id";
			starfive,tx-use-rgmii-clk;
			assigned-clocks = <0x03 0x69>;
			assigned-clock-parents = <0x03 0x65>;
			phandle = <0x9f>;

			mdio {
				#address-cells = <0x01>;
				#size-cells = <0x00>;
				compatible = "snps,dwmac-mdio";

				ethernet-phy@1 {
					reg = <0x00>;
					motorcomm,tx-clk-adj-enabled;
					motorcomm,tx-clk-100-inverted;
					motorcomm,rx-clk-drv-microamp = <0xf82>;
					motorcomm,rx-data-drv-microamp = <0xb5e>;
					rx-internal-delay-ps = <0x12c>;
					tx-internal-delay-ps = <0x00>;
					phandle = <0x42>;
				};
			};
		};

		dma-controller@16050000 {
			compatible = "starfive,jh7110-axi-dma";
			reg = <0x00 0x16050000 0x00 0x10000>;
			clocks = <0x27 0x1b 0x27 0x1c>;
			clock-names = "core-clk\0cfgr-clk";
			resets = <0x27 0x05 0x27 0x06>;
			interrupts = <0x49>;
			#dma-cells = <0x01>;
			dma-channels = <0x04>;
			snps,dma-masters = <0x01>;
			snps,data-width = <0x03>;
			snps,block-size = <0x10000 0x10000 0x10000 0x10000>;
			snps,priority = <0x00 0x01 0x02 0x03>;
			snps,axi-max-burst-len = <0x10>;
			phandle = <0x1e>;
		};

		clock-controller@17000000 {
			compatible = "starfive,jh7110-aoncrg";
			reg = <0x00 0x17000000 0x00 0x10000>;
			clocks = <0x29 0x43 0x44 0x03 0x08 0x03 0x0b 0x03 0x6c 0x45>;
			clock-names = "osc\0gmac0_rmii_refin\0gmac0_rgmii_rxin\0stg_axiahb\0apb_bus\0gmac0_gtxclk\0rtc_osc";
			#clock-cells = <0x01>;
			#reset-cells = <0x01>;
			phandle = <0x3e>;
		};

		syscon@17010000 {
			compatible = "starfive,jh7110-aon-syscon\0syscon";
			reg = <0x00 0x17010000 0x00 0x1000>;
			#power-domain-cells = <0x01>;
			phandle = <0x40>;
		};

		pinctrl@17020000 {
			compatible = "starfive,jh7110-aon-pinctrl";
			reg = <0x00 0x17020000 0x00 0x10000>;
			resets = <0x3e 0x02>;
			interrupts = <0x55>;
			interrupt-controller;
			#interrupt-cells = <0x02>;
			gpio-controller;
			#gpio-cells = <0x02>;
			phandle = <0x62>;
		};

		power-controller@17030000 {
			compatible = "starfive,jh7110-pmu";
			reg = <0x00 0x17030000 0x00 0x10000>;
			interrupts = <0x6f>;
			#power-domain-cells = <0x01>;
			phandle = <0x38>;
		};

		rtc@17040000 {
			compatible = "starfive,jh7110-rtc";
			reg = <0x00 0x17040000 0x00 0x10000>;
			interrupts = <0x0a 0x0b 0x0c>;
			interrupt-names = "rtc_ms_pulse\0rtc_sec_pulse\0rtc";
			clocks = <0x3e 0x0a 0x3e 0x0d>;
			clock-names = "pclk\0cal_clk";
			resets = <0x3e 0x07 0x3e 0x05 0x3e 0x06>;
			reset-names = "rst_osc\0rst_apb\0rst_cal";
			rtc,cal-clock-freq = <0xf4240>;
			phandle = <0xa0>;
		};

		gpu@18000000 {
			compatible = "img-gpu";
			reg = <0x00 0x18000000 0x00 0x100000 0x00 0x130c000 0x00 0x10000>;
			clocks = <0x03 0x2d 0x03 0x30 0x03 0x31 0x03 0x2e 0x03 0x2f 0x03 0x32>;
			clock-names = "clk_bv\0clk_apb\0clk_rtc\0clk_core\0clk_sys\0clk_axi";
			resets = <0x03 0x15 0x03 0x16>;
			reset-names = "rst_apb\0rst_doma";
			power-domains = <0x38 0x02>;
			interrupts = <0x52>;
			current-clock = <0x7a1200>;
			status = "okay";
			phandle = <0xa1>;
		};

		csi-bridge@19800000 {
			compatible = "starfive,jh7110-csi2rx";
			reg = <0x00 0x19800000 0x00 0x10000>;
			clocks = <0x46 0x07 0x46 0x06 0x46 0x08 0x46 0x09 0x46 0x0a 0x46 0x0b>;
			clock-names = "sys_clk\0p_clk\0pixel_if0_clk\0pixel_if1_clk\0pixel_if2_clk\0pixel_if3_clk";
			resets = <0x46 0x09 0x46 0x04 0x46 0x05 0x46 0x06 0x46 0x07 0x46 0x08>;
			reset-names = "sys\0reg_bank\0pixel_if0\0pixel_if1\0pixel_if2\0pixel_if3";
			phys = <0x47>;
			phy-names = "dphy";
			status = "disabled";
			phandle = <0xa2>;
		};

		vin_sysctl@19800000 {
			compatible = "starfive,jh7110-vin";
			reg = <0x00 0x19800000 0x00 0x10000 0x00 0x19810000 0x00 0x10000 0x00 0x19820000 0x00 0x10000 0x00 0x19840000 0x00 0x10000 0x00 0x19870000 0x00 0x30000 0x00 0x11840000 0x00 0x10000 0x00 0x17030000 0x00 0x10000 0x00 0x13020000 0x00 0x10000>;
			reg-names = "csi2rx\0vclk\0vrst\0sctrl\0isp\0trst\0pmu\0syscrg";
			clocks = <0x46 0x00 0x46 0x06 0x46 0x07 0x46 0x0d 0x46 0x02 0x46 0x0c 0x46 0x01 0x46 0x08 0x46 0x09 0x46 0x0a 0x46 0x0b 0x46 0x03 0x46 0x04 0x46 0x05 0x03 0x33 0x03 0x34>;
			clock-names = "clk_apb_func\0clk_pclk\0clk_sys_clk\0clk_wrapper_clk_c\0clk_dvp_inv\0clk_axiwr\0clk_mipi_rx0_pxl\0clk_pixel_clk_if0\0clk_pixel_clk_if1\0clk_pixel_clk_if2\0clk_pixel_clk_if3\0clk_m31dphy_cfgclk_in\0clk_m31dphy_refclk_in\0clk_m31dphy_txclkesc_lan0\0clk_ispcore_2x\0clk_isp_axi";
			resets = <0x46 0x00 0x46 0x01 0x46 0x04 0x46 0x09 0x46 0x0a 0x46 0x0b 0x46 0x05 0x46 0x06 0x46 0x07 0x46 0x08 0x46 0x02 0x46 0x03 0x03 0x29 0x03 0x2a>;
			reset-names = "rst_wrapper_p\0rst_wrapper_c\0rst_pclk\0rst_sys_clk\0rst_axird\0rst_axiwr\0rst_pixel_clk_if0\0rst_pixel_clk_if1\0rst_pixel_clk_if2\0rst_pixel_clk_if3\0rst_m31dphy_hw\0rst_m31dphy_b09_always_on\0rst_isp_top_n\0rst_isp_top_axi";
			starfive,aon-syscon = <0x40 0x00>;
			power-domains = <0x38 0x05>;
			interrupts = <0x5c 0x57 0x58 0x59 0x5a>;
			status = "okay";
			mipi_0p9-supply = <0x48>;
			phandle = <0xa3>;

			ports {
				#address-cells = <0x01>;
				#size-cells = <0x00>;

				port@1 {
					reg = <0x01>;
					#address-cells = <0x01>;
					#size-cells = <0x00>;

					endpoint@0 {
						reg = <0x00>;
						remote-endpoint = <0x49>;
						bus-type = <0x04>;
						clock-lanes = <0x04>;
						data-lanes = <0x00 0x01>;
						lane-polarities = <0x00 0x00 0x00>;
						status = "okay";
						phandle = <0x2d>;
					};

					endpoint@1 {
						reg = <0x01>;
						remote-endpoint = <0x4a>;
						bus-type = <0x04>;
						clock-lanes = <0x04>;
						data-lanes = <0x00 0x01>;
						lane-polarities = <0x00 0x00 0x00>;
						status = "okay";
						phandle = <0x2e>;
					};

					endpoint@2 {
						reg = <0x02>;
						remote-endpoint = <0x4b>;
						bus-type = <0x04>;
						clock-lanes = <0x04>;
						data-lanes = <0x00 0x01>;
						status = "okay";
						phandle = <0x2f>;
					};
				};
			};
		};

		clock-controller@19810000 {
			compatible = "starfive,jh7110-ispcrg";
			reg = <0x00 0x19810000 0x00 0x10000>;
			clocks = <0x03 0x33 0x03 0x34 0x03 0x35 0x4c>;
			clock-names = "isp_top_core\0isp_top_axi\0noc_bus_isp_axi\0dvp_clk";
			resets = <0x03 0x29 0x03 0x2a 0x03 0x1c>;
			#clock-cells = <0x01>;
			#reset-cells = <0x01>;
			power-domains = <0x38 0x05>;
			phandle = <0x46>;
		};

		phy@19820000 {
			compatible = "starfive,jh7110-dphy-rx";
			reg = <0x00 0x19820000 0x00 0x10000>;
			clocks = <0x46 0x03 0x46 0x04 0x46 0x05>;
			clock-names = "cfg\0ref\0tx";
			resets = <0x46 0x02 0x46 0x03>;
			power-domains = <0x40 0x01>;
			#phy-cells = <0x00>;
			phandle = <0x47>;
		};

		dc8200@29400000 {
			compatible = "starfive,jh7110-dc8200\0verisilicon,dc8200";
			verisilicon,dss-syscon = <0x4d>;
			reg = <0x00 0x29400000 0x00 0x100 0x00 0x29400800 0x00 0x2000 0x00 0x17030000 0x00 0x1000>;
			interrupts = <0x5f>;
			clocks = <0x03 0x3c 0x03 0x3a 0x03 0x3e 0x03 0x3d 0x4e 0x07 0x4e 0x08 0x4e 0x04 0x4e 0x05 0x4e 0x06 0x03 0x3e 0x4e 0x09 0x4f 0x4e 0x01>;
			clock-names = "noc_disp\0vout_src\0top_vout_axi\0top_vout_ahb\0pix_clk\0vout_pix1\0axi_clk\0core_clk\0vout_ahb\0vout_top_axi\0vout_top_lcd\0hdmitx0_pixelclk\0dc8200_pix0";
			resets = <0x03 0x2b 0x4e 0x00 0x4e 0x01 0x4e 0x02 0x03 0x1a>;
			reset-names = "rst_vout_src\0rst_axi\0rst_ahb\0rst_core\0rst_noc_disp";
			status = "okay";
			phandle = <0xa4>;

			port {
				#address-cells = <0x01>;
				#size-cells = <0x00>;
				phandle = <0xa5>;

				endpoint@0 {
					reg = <0x00>;
					remote-endpoint = <0x50>;
					phandle = <0x0a>;
				};

				endpoint@1 {
					reg = <0x01>;
					remote-endpoint = <0x51>;
					phandle = <0x56>;
				};

				endpoint@2 {
					reg = <0x02>;
					remote-endpoint = <0x52>;
					phandle = <0x0b>;
				};
			};
		};

		hdmi@29590000 {
			compatible = "starfive,jh7110-hdmi\0inno,hdmi";
			reg = <0x00 0x29590000 0x00 0x4000>;
			interrupts = <0x63>;
			clocks = <0x4e 0x11 0x4e 0x0f 0x4e 0x10 0x4f>;
			clock-names = "sysclk\0mclk\0bclk\0pclk";
			resets = <0x4e 0x09>;
			reset-names = "hdmi_tx";
			#sound-dai-cells = <0x00>;
			status = "okay";
			pinctrl-names = "default";
			pinctrl-0 = <0x53>;
			hpd-gpio = <0x1a 0x0f 0x00>;
			hdmi_0p9-supply = <0x54>;
			hdmi_1p8-supply = <0x55>;
			phandle = <0x68>;

			port {
				#address-cells = <0x01>;
				#size-cells = <0x00>;
				phandle = <0xa6>;

				endpoint@0 {
					reg = <0x00>;
					remote-endpoint = <0x56>;
					phandle = <0x51>;
				};
			};
		};

		dssctrl@295B0000 {
			compatible = "starfive,jh7110-dssctrl\0verisilicon,dss-ctrl\0syscon";
			reg = <0x00 0x295b0000 0x00 0x90>;
			phandle = <0x4d>;
		};

		clock-controller@295c0000 {
			compatible = "starfive,jh7110-voutcrg";
			reg = <0x00 0x295c0000 0x00 0x10000>;
			clocks = <0x03 0x3a 0x03 0x3d 0x03 0x3e 0x03 0x3f 0x03 0xa5 0x4f>;
			clock-names = "vout_src\0vout_top_ahb\0vout_top_axi\0vout_top_hdmitx0_mclk\0i2stx0_bclk\0hdmitx0_pixelclk";
			resets = <0x03 0x2b>;
			#clock-cells = <0x01>;
			#reset-cells = <0x01>;
			power-domains = <0x38 0x04>;
			phandle = <0x4e>;
		};

		mipi@295d0000 {
			compatible = "starfive,jh7110-mipi_dsi\0cdns,dsi";
			reg = <0x00 0x295d0000 0x00 0x10000>;
			interrupts = <0x62>;
			reg-names = "dsi";
			clocks = <0x4e 0x0b 0x4e 0x0a 0x4e 0x0d 0x4e 0x0c>;
			clock-names = "dpi\0apb\0txesc\0sys";
			resets = <0x4e 0x03 0x4e 0x04 0x4e 0x05 0x4e 0x06 0x4e 0x07 0x4e 0x08>;
			reset-names = "dsi_dpi\0dsi_apb\0dsi_rxesc\0dsi_sys\0dsi_txbytehs\0dsi_txesc";
			phys = <0x57>;
			phy-names = "dphy";
			status = "okay";
			phandle = <0xa7>;

			ports {
				#address-cells = <0x01>;
				#size-cells = <0x00>;

				port@0 {
					reg = <0x00>;
					#address-cells = <0x01>;
					#size-cells = <0x00>;

					endpoint@0 {
						reg = <0x00>;
						remote-endpoint = <0x58>;
						phandle = <0x19>;
					};

					endpoint@1 {
						reg = <0x01>;
						remote-endpoint = <0x59>;
						phandle = <0x1b>;
					};
				};

				port@1 {
					reg = <0x01>;

					endpoint {
						remote-endpoint = <0x5a>;
						phandle = <0x0c>;
					};
				};
			};
		};

		mipi-dphy@295e0000 {
			compatible = "starfive,jh7110-mipi-dphy-tx\0m31,mipi-dphy-tx";
			reg = <0x00 0x295e0000 0x00 0x10000>;
			clocks = <0x4e 0x0e>;
			clock-names = "dphy_txesc";
			resets = <0x4e 0x0a 0x4e 0x0b>;
			reset-names = "dphy_sys\0dphy_txbytehs";
			#phy-cells = <0x00>;
			status = "okay";
			phandle = <0x57>;
		};

		e24@6e210000 {
			compatible = "starfive,e24";
			dma-coherent;
			reg = <0x00 0x6e210000 0x00 0x1000 0x00 0x6e211000 0x00 0x3f000>;
			reg-names = "ecmd\0espace";
			clocks = <0x27 0x18 0x27 0x19 0x27 0x1a>;
			clock-names = "clk_rtc\0clk_core\0clk_dbg";
			resets = <0x27 0x04>;
			reset-names = "e24_core";
			starfive,stg-syscon = <0x26>;
			interrupt-parent = <0x10>;
			firmware-name = "e24_elf";
			irq-mode = <0x01>;
			mbox-names = "tx\0rx";
			mboxes = <0x0d 0x00 0x02 0x0d 0x02 0x00>;
			#address-cells = <0x01>;
			#size-cells = <0x01>;
			ranges = <0x6ce00000 0x00 0x6ce00000 0x1600000>;
			status = "okay";
			memory-region = <0x5b>;
			phandle = <0xa8>;

			dsp@0 {
			};
		};

		pcie@940000000 {
			compatible = "starfive,jh7110-pcie";
			reg = <0x09 0x40000000 0x00 0x1000000 0x00 0x2b000000 0x00 0x100000>;
			reg-names = "cfg\0apb";
			linux,pci-domain = <0x00>;
			#address-cells = <0x03>;
			#size-cells = <0x02>;
			#interrupt-cells = <0x01>;
			ranges = <0x82000000 0x00 0x30000000 0x00 0x30000000 0x00 0x8000000 0xc3000000 0x09 0x00 0x09 0x00 0x00 0x40000000>;
			interrupts = <0x38>;
			interrupt-map-mask = <0x00 0x00 0x00 0x07>;
			interrupt-map = <0x00 0x00 0x00 0x01 0x5c 0x01 0x00 0x00 0x00 0x02 0x5c 0x02 0x00 0x00 0x00 0x03 0x5c 0x03 0x00 0x00 0x00 0x04 0x5c 0x04>;
			msi-controller;
			device_type = "pci";
			starfive,stg-syscon = <0x26>;
			bus-range = <0x00 0xff>;
			clocks = <0x03 0x60 0x27 0x0a 0x27 0x08 0x27 0x09>;
			clock-names = "noc\0tl\0axi_mst0\0apb";
			resets = <0x27 0x0b 0x27 0x0c 0x27 0x0d 0x27 0x0e 0x27 0x0f 0x27 0x10>;
			reset-names = "mst0\0slv0\0slv\0brg\0core\0apb";
			status = "okay";
			perst-gpios = <0x1a 0x1a 0x01>;
			phys = <0x5d>;
			pinctrl-names = "default";
			pinctrl-0 = <0x5e>;
			phandle = <0xa9>;

			interrupt-controller {
				#address-cells = <0x00>;
				#interrupt-cells = <0x01>;
				interrupt-controller;
				phandle = <0x5c>;
			};
		};

		pcie@9c0000000 {
			compatible = "starfive,jh7110-pcie";
			reg = <0x09 0xc0000000 0x00 0x1000000 0x00 0x2c000000 0x00 0x100000>;
			reg-names = "cfg\0apb";
			linux,pci-domain = <0x01>;
			#address-cells = <0x03>;
			#size-cells = <0x02>;
			#interrupt-cells = <0x01>;
			ranges = <0x82000000 0x00 0x38000000 0x00 0x38000000 0x00 0x8000000 0xc3000000 0x09 0x80000000 0x09 0x80000000 0x00 0x40000000>;
			interrupts = <0x39>;
			interrupt-map-mask = <0x00 0x00 0x00 0x07>;
			interrupt-map = <0x00 0x00 0x00 0x01 0x5f 0x01 0x00 0x00 0x00 0x02 0x5f 0x02 0x00 0x00 0x00 0x03 0x5f 0x03 0x00 0x00 0x00 0x04 0x5f 0x04>;
			msi-controller;
			device_type = "pci";
			starfive,stg-syscon = <0x26>;
			bus-range = <0x00 0xff>;
			clocks = <0x03 0x60 0x27 0x0d 0x27 0x0b 0x27 0x0c>;
			clock-names = "noc\0tl\0axi_mst0\0apb";
			resets = <0x27 0x11 0x27 0x12 0x27 0x13 0x27 0x14 0x27 0x15 0x27 0x16>;
			reset-names = "mst0\0slv0\0slv\0brg\0core\0apb";
			status = "okay";
			perst-gpios = <0x1a 0x1c 0x01>;
			phys = <0x60>;
			pinctrl-names = "default";
			pinctrl-0 = <0x61>;
			phandle = <0xaa>;

			interrupt-controller {
				#address-cells = <0x00>;
				#interrupt-cells = <0x01>;
				interrupt-controller;
				phandle = <0x5f>;
			};
		};
	};

	aliases {
		ethernet0 = "/soc/ethernet@16030000";
		ethernet1 = "/soc/ethernet@16040000";
		i2c0 = "/soc/i2c@10030000";
		i2c1 = "/soc/i2c@10040000";
		i2c2 = "/soc/i2c@10050000";
		i2c3 = "/soc/i2c@12030000";
		i2c4 = "/soc/i2c@12040000";
		i2c5 = "/soc/i2c@12050000";
		i2c6 = "/soc/i2c@12060000";
		mmc0 = "/soc/mmc@16010000";
		mmc1 = "/soc/mmc@16020000";
		pcie0 = "/soc/pcie@940000000";
		pcie1 = "/soc/pcie@9c0000000";
		serial0 = "/soc/serial@10000000";
		serial3 = "/soc/serial@12000000";
	};

	chosen {
		stdout-path = "serial0:115200n8";
	};

	memory@40000000 {
		device_type = "memory";
		reg = <0x00 0x40000000 0x01 0x00>;
	};

	reserved-memory {
		#address-cells = <0x02>;
		#size-cells = <0x02>;
		ranges;

		linux,cma {
			compatible = "shared-dma-pool";
			reusable;
			size = <0x00 0x20000000>;
			alignment = <0x00 0x1000>;
			alloc-ranges = <0x00 0x70000000 0x00 0x20000000>;
			linux,cma-default;
		};

		e24@c0000000 {
			reg = <0x00 0x6ce00000 0x00 0x1600000>;
			phandle = <0x5b>;
		};

		xrpbuffer@f0000000 {
			reg = <0x00 0x69c00000 0x00 0x1ffffff 0x00 0x6bc00000 0x00 0x1000 0x00 0x6bc01000 0x00 0xfff000 0x00 0x6cc00000 0x00 0x1000>;
			phandle = <0xab>;
		};
	};

	leds {
		compatible = "gpio-leds";

		led-ack {
			gpios = <0x62 0x03 0x00>;
			color = <0x02>;
			function = "heartbeat";
			linux,default-trigger = "heartbeat";
			label = "ack";
		};
	};

	gpio-restart {
		compatible = "gpio-restart";
		gpios = <0x1a 0x23 0x00>;
		priority = <0xa0>;
	};

	pwmdac-codec {
		compatible = "linux,spdif-dit";
		#sound-dai-cells = <0x00>;
		phandle = <0x65>;
	};

	snd-card3 {
		compatible = "simple-audio-card";
		simple-audio-card,name = "Starfive-PWMDAC-Sound-Card";
		#address-cells = <0x01>;
		#size-cells = <0x00>;
		phandle = <0xac>;

		simple-audio-card,dai-link@0 {
			reg = <0x00>;
			format = "left_j";
			bitclock-master = <0x63>;
			frame-master = <0x63>;

			cpu {
				sound-dai = <0x64>;
				phandle = <0x63>;
			};

			codec {
				sound-dai = <0x65>;
			};
		};
	};

	snd-card1 {
		compatible = "simple-audio-card";
		#address-cells = <0x01>;
		#size-cells = <0x00>;
		simple-audio-card,name = "Starfive-HDMI-Sound-Card";
		phandle = <0xad>;

		simple-audio-card,dai-link@0 {
			reg = <0x00>;
			format = "i2s";
			bitclock-master = <0x66>;
			frame-master = <0x66>;
			mclk-fs = <0x100>;
			status = "okay";

			cpu {
				sound-dai = <0x67>;
				phandle = <0x66>;
			};

			codec {
				sound-dai = <0x68>;
			};
		};
	};

	ac108_mclk {
		compatible = "fixed-clock";
		#clock-cells = <0x00>;
		clock-frequency = <0x16e3600>;
		phandle = <0xae>;
	};

	clk-ext-camera {
		compatible = "fixed-clock";
		#clock-cells = <0x00>;
		clock-frequency = <0x16e3600>;
		phandle = <0x2c>;
	};

	wm8960_mclk {
		compatible = "fixed-clock";
		#clock-cells = <0x00>;
		clock-frequency = <0x1770000>;
		phandle = <0xaf>;
	};

	__symbols__ {
		S7_0 = "/cpus/cpu@0";
		cpu0_intc = "/cpus/cpu@0/interrupt-controller";
		U74_1 = "/cpus/cpu@1";
		cpu1_intc = "/cpus/cpu@1/interrupt-controller";
		U74_2 = "/cpus/cpu@2";
		cpu2_intc = "/cpus/cpu@2/interrupt-controller";
		U74_3 = "/cpus/cpu@3";
		cpu3_intc = "/cpus/cpu@3/interrupt-controller";
		U74_4 = "/cpus/cpu@4";
		cpu4_intc = "/cpus/cpu@4/interrupt-controller";
		cpu_opp = "/opp-table-0";
		display = "/display-subsystem";
		dsi_output = "/dsi-output";
		mipi_in = "/dsi-output/ports/port@0/endpoint";
		sf_dpi_output = "/dsi-output/ports/port@1/endpoint";
		mailbox_client0 = "/mailbox_client";
		rgb_output = "/rgb-output";
		hdmi_input0 = "/rgb-output/ports/port@0/endpoint@0";
		tda988x_pin = "/tda988x_pin";
		cpu_alert0 = "/thermal-zones/cpu-thermal/trips/cpu_alert0";
		dvp_clk = "/dvp-clock";
		gmac0_rgmii_rxin = "/gmac0-rgmii-rxin-clock";
		gmac0_rmii_refin = "/gmac0-rmii-refin-clock";
		gmac1_rgmii_rxin = "/gmac1-rgmii-rxin-clock";
		gmac1_rmii_refin = "/gmac1-rmii-refin-clock";
		hdmitx0_pixelclk = "/hdmitx0-pixel-clock";
		i2srx_bclk_ext = "/i2srx-bclk-ext-clock";
		i2srx_lrck_ext = "/i2srx-lrck-ext-clock";
		i2stx_bclk_ext = "/i2stx-bclk-ext-clock";
		i2stx_lrck_ext = "/i2stx-lrck-ext-clock";
		mclk_ext = "/mclk-ext-clock";
		osc = "/oscillator";
		rtc_osc = "/rtc-oscillator";
		stmmac_axi_setup = "/stmmac-axi-config";
		tdm_ext = "/tdm-ext-clock";
		clint = "/soc/timer@2000000";
		ccache = "/soc/cache-controller@2010000";
		plic = "/soc/interrupt-controller@c000000";
		uart0 = "/soc/serial@10000000";
		uart1 = "/soc/serial@10010000";
		uart2 = "/soc/serial@10020000";
		i2c0 = "/soc/i2c@10030000";
		i2c1 = "/soc/i2c@10040000";
		i2c2 = "/soc/i2c@10050000";
		panel_out0 = "/soc/i2c@10050000/seeed_plane_i2c@45/port/endpoint";
		tinker_ft5406 = "/soc/i2c@10050000/tinker_ft5406@38";
		panel_out1 = "/soc/i2c@10050000/panel_radxa@19/port/endpoint";
		spi0 = "/soc/spi@10060000";
		spi_dev0 = "/soc/spi@10060000/spi@0";
		spi1 = "/soc/spi@10070000";
		spi2 = "/soc/spi@10080000";
		tdm = "/soc/tdm@10090000";
		spdif = "/soc/spdif@100a0000";
		pwmdac = "/soc/pwmdac@100b0000";
		pdm = "/soc/pdm@100d0000";
		i2srx_mst = "/soc/i2srx_mst@100e0000";
		i2srx = "/soc/i2s@100e0000";
		usb0 = "/soc/usb@10100000";
		usb_cdns3 = "/soc/usb@10100000/usb@0";
		usbphy0 = "/soc/phy@10200000";
		pciephy0 = "/soc/phy@10210000";
		pciephy1 = "/soc/phy@10220000";
		stgcrg = "/soc/clock-controller@10230000";
		xrp = "/soc/xrp@10230000";
		stg_syscon = "/soc/syscon@10240000";
		uart3 = "/soc/serial@12000000";
		uart4 = "/soc/serial@12010000";
		uart5 = "/soc/serial@12020000";
		i2c3 = "/soc/i2c@12030000";
		i2c4 = "/soc/i2c@12040000";
		i2c5 = "/soc/i2c@12050000";
		axp15060 = "/soc/i2c@12050000/pmic@36";
		mipi_0p9 = "/soc/i2c@12050000/pmic@36/regulators/ALDO1";
		hdmi_0p9 = "/soc/i2c@12050000/pmic@36/regulators/ALDO5";
		hdmi_1p8 = "/soc/i2c@12050000/pmic@36/regulators/ALDO3";
		vcc_3v3 = "/soc/i2c@12050000/pmic@36/regulators/dcdc1";
		vdd_cpu = "/soc/i2c@12050000/pmic@36/regulators/dcdc2";
		emmc_vdd = "/soc/i2c@12050000/pmic@36/regulators/aldo4";
		i2c6 = "/soc/i2c@12060000";
		imx219 = "/soc/i2c@12060000/imx219@10";
		imx219_to_csi2rx0 = "/soc/i2c@12060000/imx219@10/port/endpoint";
		imx708 = "/soc/i2c@12060000/imx708@1a";
		imx708_to_csi2rx0 = "/soc/i2c@12060000/imx708@1a/port/endpoint";
		ov4689 = "/soc/i2c@12060000/ov4689@36";
		ov4689_to_csi2rx0 = "/soc/i2c@12060000/ov4689@36/port/endpoint";
		spi3 = "/soc/spi@12070000";
		spi4 = "/soc/spi@12080000";
		spi5 = "/soc/spi@12090000";
		spi6 = "/soc/spi@120a0000";
		i2stx0 = "/soc/i2s@120b0000";
		i2stx1 = "/soc/i2s@120c0000";
		pwm = "/soc/pwm@120d0000";
		sfctemp = "/soc/temperature-sensor@120e0000";
		qspi = "/soc/spi@13010000";
		nor_flash = "/soc/spi@13010000/flash@0";
		syscrg = "/soc/clock-controller@13020000";
		sys_syscon = "/soc/syscon@13030000";
		pllclk = "/soc/syscon@13030000/clock-controller";
		sysgpio = "/soc/pinctrl@13040000";
		i2c0_pins = "/soc/pinctrl@13040000/i2c0-0";
		i2c2_pins = "/soc/pinctrl@13040000/i2c2-0";
		i2c5_pins = "/soc/pinctrl@13040000/i2c5-0";
		i2c6_pins = "/soc/pinctrl@13040000/i2c6-0";
		i2srx_pins = "/soc/pinctrl@13040000/i2srx-0";
		i2stx1_pins = "/soc/pinctrl@13040000/i2stx1-0";
		mclk_ext_pins = "/soc/pinctrl@13040000/mclk-ext-0";
		mmc0_pins = "/soc/pinctrl@13040000/mmc0-0";
		mmc1_pins = "/soc/pinctrl@13040000/mmc1-0";
		pcie0_pins = "/soc/pinctrl@13040000/pcie0-0";
		pcie1_pins = "/soc/pinctrl@13040000/pcie1-0";
		pwm_pins = "/soc/pinctrl@13040000/pwm-0";
		pwmdac_pins = "/soc/pinctrl@13040000/pwmdac-0";
		spi0_pins = "/soc/pinctrl@13040000/spi0-0";
		tdm_pins = "/soc/pinctrl@13040000/tdm-0";
		uart0_pins = "/soc/pinctrl@13040000/uart0-0";
		hdmi_pins = "/soc/pinctrl@13040000/hdmi-0";
		mailbox_contrl0 = "/soc/mailbox@13060000";
		jpu = "/soc/jpu@13090000";
		vpu_dec = "/soc/vpu_dec@130a0000";
		vpu_enc = "/soc/vpu_enc@130b0000";
		can0 = "/soc/can@130d0000";
		can1 = "/soc/can@130e0000";
		crypto = "/soc/crypto@16000000";
		sdma = "/soc/dma-controller@16008000";
		rng = "/soc/rng@1600c000";
		mmc0 = "/soc/mmc@16010000";
		mmc1 = "/soc/mmc@16020000";
		gmac0 = "/soc/ethernet@16030000";
		phy0 = "/soc/ethernet@16030000/mdio/ethernet-phy@0";
		gmac1 = "/soc/ethernet@16040000";
		phy1 = "/soc/ethernet@16040000/mdio/ethernet-phy@1";
		dma = "/soc/dma-controller@16050000";
		aoncrg = "/soc/clock-controller@17000000";
		aon_syscon = "/soc/syscon@17010000";
		aongpio = "/soc/pinctrl@17020000";
		pwrc = "/soc/power-controller@17030000";
		rtc = "/soc/rtc@17040000";
		gpu = "/soc/gpu@18000000";
		csi2rx = "/soc/csi-bridge@19800000";
		vin_sysctl = "/soc/vin_sysctl@19800000";
		csi2rx0_from_imx219 = "/soc/vin_sysctl@19800000/ports/port@1/endpoint@0";
		csi2rx0_from_imx708 = "/soc/vin_sysctl@19800000/ports/port@1/endpoint@1";
		csi2rx0_from_ov4689 = "/soc/vin_sysctl@19800000/ports/port@1/endpoint@2";
		ispcrg = "/soc/clock-controller@19810000";
		csi_phy = "/soc/phy@19820000";
		dc8200 = "/soc/dc8200@29400000";
		dc_out = "/soc/dc8200@29400000/port";
		dc_out_dpi0 = "/soc/dc8200@29400000/port/endpoint@0";
		dc_out_dpi1 = "/soc/dc8200@29400000/port/endpoint@1";
		dc_out_dpi2 = "/soc/dc8200@29400000/port/endpoint@2";
		hdmi = "/soc/hdmi@29590000";
		hdmi_in = "/soc/hdmi@29590000/port";
		hdmi_in_lcdc = "/soc/hdmi@29590000/port/endpoint@0";
		dssctrl = "/soc/dssctrl@295B0000";
		voutcrg = "/soc/clock-controller@295c0000";
		mipi_dsi = "/soc/mipi@295d0000";
		dsi0_output = "/soc/mipi@295d0000/ports/port@0/endpoint@0";
		dsi1_output = "/soc/mipi@295d0000/ports/port@0/endpoint@1";
		dsi_in_port = "/soc/mipi@295d0000/ports/port@1/endpoint";
		mipi_dphy = "/soc/mipi-dphy@295e0000";
		co_process = "/soc/e24@6e210000";
		pcie0 = "/soc/pcie@940000000";
		pcie_intc0 = "/soc/pcie@940000000/interrupt-controller";
		pcie1 = "/soc/pcie@9c0000000";
		pcie_intc1 = "/soc/pcie@9c0000000/interrupt-controller";
		e24_mem = "/reserved-memory/e24@c0000000";
		xrp_reserved = "/reserved-memory/xrpbuffer@f0000000";
		pwmdac_codec = "/pwmdac-codec";
		sound3 = "/snd-card3";
		sndcpu0 = "/snd-card3/simple-audio-card,dai-link@0/cpu";
		sound1 = "/snd-card1";
		sndi2s0 = "/snd-card1/simple-audio-card,dai-link@0/cpu";
		ac108_mclk = "/ac108_mclk";
		clk_ext_camera = "/clk-ext-camera";
		wm8960_mclk = "/wm8960_mclk";
	};
};
